VERSION "1.2"

NS_ :

BS_:

BU_: RPI STM32_LEFT STM32_RIGHT ESP32_AUX

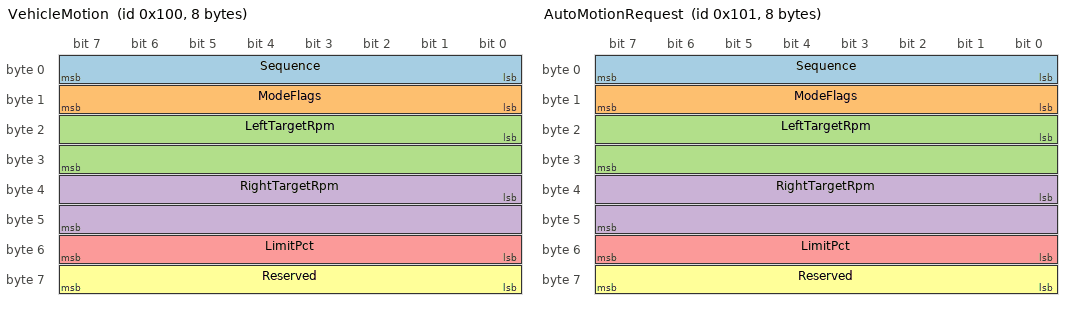
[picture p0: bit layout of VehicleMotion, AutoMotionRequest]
BO_ 256 VehicleMotion: 8 ESP32_AUX
 SG_ Sequence : 0|8@1+ (1,0) [0|255] "" STM32_LEFT,STM32_RIGHT
 SG_ ModeFlags : 8|8@1+ (1,0) [0|255] "" STM32_LEFT,STM32_RIGHT
 SG_ LeftTargetRpm : 16|16@1- (1,0) [-32768|32767] "rpm" STM32_LEFT
 SG_ RightTargetRpm : 32|16@1- (1,0) [-32768|32767] "rpm" STM32_RIGHT
 SG_ LimitPct : 48|8@1+ (1,0) [0|100] "%" STM32_LEFT,STM32_RIGHT
 SG_ Reserved : 56|8@1+ (1,0) [0|255] "" STM32_LEFT,STM32_RIGHT

BO_ 257 AutoMotionRequest: 8 RPI
 SG_ Sequence : 0|8@1+ (1,0) [0|255] "" ESP32_AUX
 SG_ ModeFlags : 8|8@1+ (1,0) [0|255] "" ESP32_AUX
 SG_ LeftTargetRpm : 16|16@1- (1,0) [-32768|32767] "rpm" ESP32_AUX
 SG_ RightTargetRpm : 32|16@1- (1,0) [-32768|32767] "rpm" ESP32_AUX
 SG_ LimitPct : 48|8@1+ (1,0) [0|100] "%" ESP32_AUX
 SG_ Reserved : 56|8@1+ (1,0) [0|255] "" ESP32_AUX

BO_ 272 SystemEnable: 2 ESP32_AUX
 SG_ Enabled : 0|8@1+ (1,0) [0|1] "" STM32_LEFT,STM32_RIGHT,RPI
 SG_ EmergencyStop : 8|8@1+ (1,0) [0|1] "" STM32_LEFT,STM32_RIGHT,RPI

BO_ 273 AutoEnableRequest: 2 RPI
 SG_ Enabled : 0|8@1+ (1,0) [0|1] "" ESP32_AUX
 SG_ EmergencyStop : 8|8@1+ (1,0) [0|1] "" ESP32_AUX

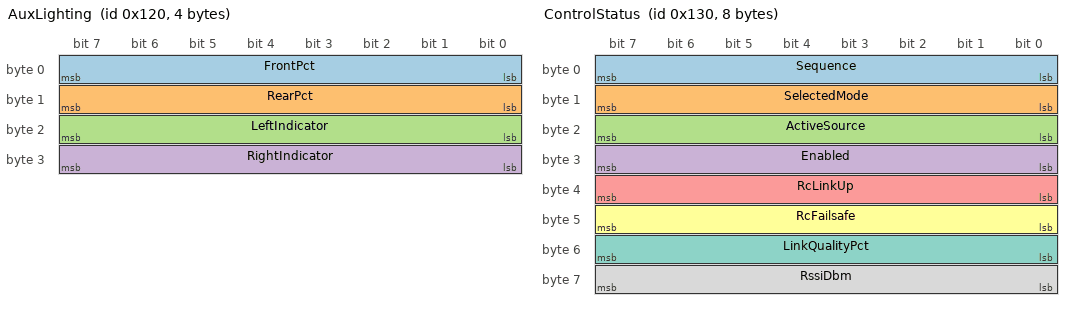
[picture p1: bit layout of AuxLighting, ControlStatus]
BO_ 288 AuxLighting: 4 RPI
 SG_ FrontPct : 0|8@1+ (1,0) [0|100] "%" ESP32_AUX
 SG_ RearPct : 8|8@1+ (1,0) [0|100] "%" ESP32_AUX
 SG_ LeftIndicator : 16|8@1+ (1,0) [0|1] "" ESP32_AUX
 SG_ RightIndicator : 24|8@1+ (1,0) [0|1] "" ESP32_AUX

BO_ 304 ControlStatus: 8 ESP32_AUX
 SG_ Sequence : 0|8@1+ (1,0) [0|255] "" RPI
 SG_ SelectedMode : 8|8@1+ (1,0) [0|2] "" RPI
 SG_ ActiveSource : 16|8@1+ (1,0) [0|2] "" RPI
 SG_ Enabled : 24|8@1+ (1,0) [0|1] "" RPI
 SG_ RcLinkUp : 32|8@1+ (1,0) [0|1] "" RPI
 SG_ RcFailsafe : 40|8@1+ (1,0) [0|1] "" RPI
 SG_ LinkQualityPct : 48|8@1+ (1,0) [0|100] "%" RPI
 SG_ RssiDbm : 56|8@1- (1,0) [-128|127] "dBm" RPI

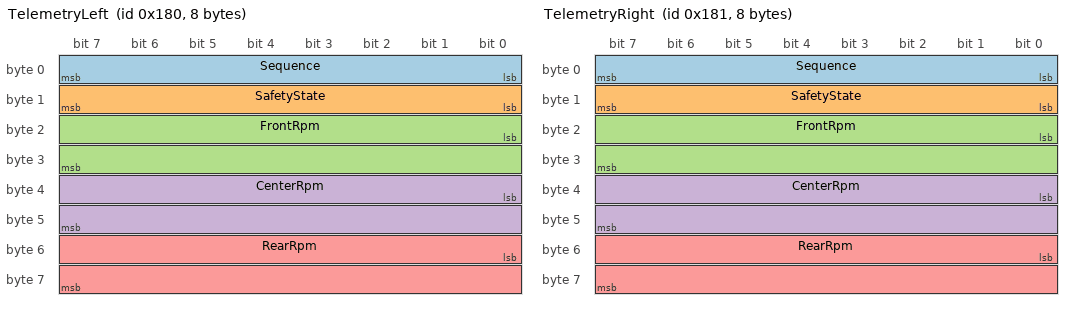
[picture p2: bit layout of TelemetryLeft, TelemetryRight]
BO_ 384 TelemetryLeft: 8 STM32_LEFT
 SG_ Sequence : 0|8@1+ (1,0) [0|255] "" RPI,ESP32_AUX
 SG_ SafetyState : 8|8@1+ (1,0) [0|255] "" RPI,ESP32_AUX
 SG_ FrontRpm : 16|16@1- (1,0) [-32768|32767] "rpm" RPI,ESP32_AUX
 SG_ CenterRpm : 32|16@1- (1,0) [-32768|32767] "rpm" RPI,ESP32_AUX
 SG_ RearRpm : 48|16@1- (1,0) [-32768|32767] "rpm" RPI,ESP32_AUX

BO_ 385 TelemetryRight: 8 STM32_RIGHT
 SG_ Sequence : 0|8@1+ (1,0) [0|255] "" RPI,ESP32_AUX
 SG_ SafetyState : 8|8@1+ (1,0) [0|255] "" RPI,ESP32_AUX
 SG_ FrontRpm : 16|16@1- (1,0) [-32768|32767] "rpm" RPI,ESP32_AUX
 SG_ CenterRpm : 32|16@1- (1,0) [-32768|32767] "rpm" RPI,ESP32_AUX
 SG_ RearRpm : 48|16@1- (1,0) [-32768|32767] "rpm" RPI,ESP32_AUX

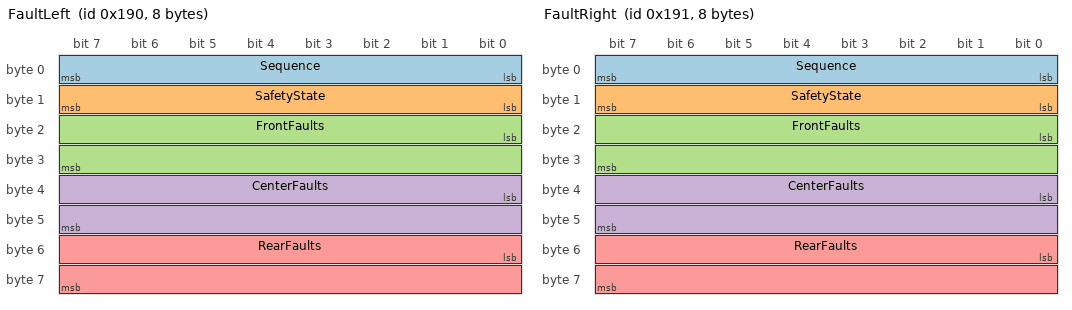
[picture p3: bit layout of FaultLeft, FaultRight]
BO_ 400 FaultLeft: 8 STM32_LEFT
 SG_ Sequence : 0|8@1+ (1,0) [0|255] "" RPI,ESP32_AUX
 SG_ SafetyState : 8|8@1+ (1,0) [0|255] "" RPI,ESP32_AUX
 SG_ FrontFaults : 16|16@1+ (1,0) [0|65535] "" RPI,ESP32_AUX
 SG_ CenterFaults : 32|16@1+ (1,0) [0|65535] "" RPI,ESP32_AUX
 SG_ RearFaults : 48|16@1+ (1,0) [0|65535] "" RPI,ESP32_AUX

BO_ 401 FaultRight: 8 STM32_RIGHT
 SG_ Sequence : 0|8@1+ (1,0) [0|255] "" RPI,ESP32_AUX
 SG_ SafetyState : 8|8@1+ (1,0) [0|255] "" RPI,ESP32_AUX
 SG_ FrontFaults : 16|16@1+ (1,0) [0|65535] "" RPI,ESP32_AUX
 SG_ CenterFaults : 32|16@1+ (1,0) [0|65535] "" RPI,ESP32_AUX
 SG_ RearFaults : 48|16@1+ (1,0) [0|65535] "" RPI,ESP32_AUX

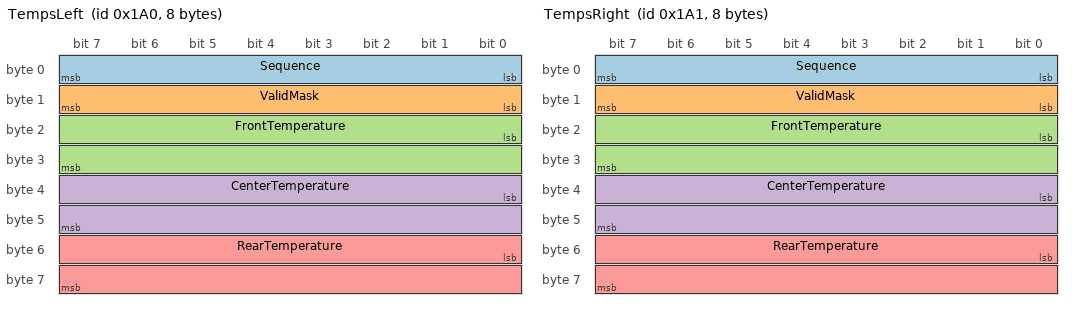
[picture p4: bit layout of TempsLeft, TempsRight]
BO_ 416 TempsLeft: 8 STM32_LEFT
 SG_ Sequence : 0|8@1+ (1,0) [0|255] "" RPI,ESP32_AUX
 SG_ ValidMask : 8|8@1+ (1,0) [0|7] "" RPI,ESP32_AUX
 SG_ FrontTemperature : 16|16@1- (0.01,0) [-327.68|327.67] "degC" RPI,ESP32_AUX
 SG_ CenterTemperature : 32|16@1- (0.01,0) [-327.68|327.67] "degC" RPI,ESP32_AUX
 SG_ RearTemperature : 48|16@1- (0.01,0) [-327.68|327.67] "degC" RPI,ESP32_AUX

BO_ 417 TempsRight: 8 STM32_RIGHT
 SG_ Sequence : 0|8@1+ (1,0) [0|255] "" RPI,ESP32_AUX
 SG_ ValidMask : 8|8@1+ (1,0) [0|7] "" RPI,ESP32_AUX
 SG_ FrontTemperature : 16|16@1- (0.01,0) [-327.68|327.67] "degC" RPI,ESP32_AUX
 SG_ CenterTemperature : 32|16@1- (0.01,0) [-327.68|327.67] "degC" RPI,ESP32_AUX
 SG_ RearTemperature : 48|16@1- (0.01,0) [-327.68|327.67] "degC" RPI,ESP32_AUX

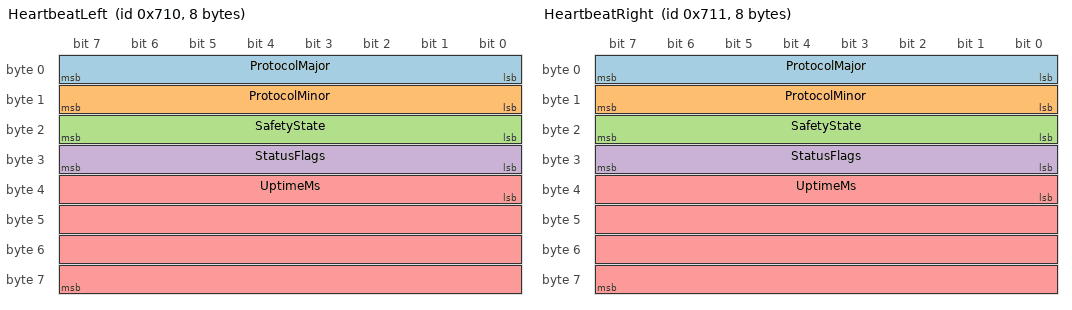
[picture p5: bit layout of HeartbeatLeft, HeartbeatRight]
BO_ 1808 HeartbeatLeft: 8 STM32_LEFT
 SG_ ProtocolMajor : 0|8@1+ (1,0) [0|255] "" RPI,ESP32_AUX
 SG_ ProtocolMinor : 8|8@1+ (1,0) [0|255] "" RPI,ESP32_AUX
 SG_ SafetyState : 16|8@1+ (1,0) [0|255] "" RPI,ESP32_AUX
 SG_ StatusFlags : 24|8@1+ (1,0) [0|255] "" RPI,ESP32_AUX
 SG_ UptimeMs : 32|32@1+ (1,0) [0|4294967295] "ms" RPI,ESP32_AUX

BO_ 1809 HeartbeatRight: 8 STM32_RIGHT
 SG_ ProtocolMajor : 0|8@1+ (1,0) [0|255] "" RPI,ESP32_AUX
 SG_ ProtocolMinor : 8|8@1+ (1,0) [0|255] "" RPI,ESP32_AUX
 SG_ SafetyState : 16|8@1+ (1,0) [0|255] "" RPI,ESP32_AUX
 SG_ StatusFlags : 24|8@1+ (1,0) [0|255] "" RPI,ESP32_AUX
 SG_ UptimeMs : 32|32@1+ (1,0) [0|4294967295] "ms" RPI,ESP32_AUX

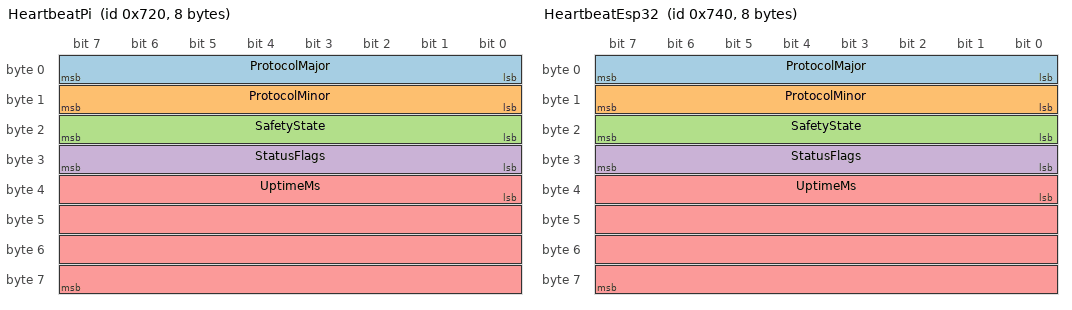
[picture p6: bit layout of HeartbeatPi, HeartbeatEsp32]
BO_ 1824 HeartbeatPi: 8 RPI
 SG_ ProtocolMajor : 0|8@1+ (1,0) [0|255] "" STM32_LEFT,STM32_RIGHT,ESP32_AUX
 SG_ ProtocolMinor : 8|8@1+ (1,0) [0|255] "" STM32_LEFT,STM32_RIGHT,ESP32_AUX
 SG_ SafetyState : 16|8@1+ (1,0) [0|255] "" STM32_LEFT,STM32_RIGHT,ESP32_AUX
 SG_ StatusFlags : 24|8@1+ (1,0) [0|255] "" STM32_LEFT,STM32_RIGHT,ESP32_AUX
 SG_ UptimeMs : 32|32@1+ (1,0) [0|4294967295] "ms" STM32_LEFT,STM32_RIGHT,ESP32_AUX

BO_ 1856 HeartbeatEsp32: 8 ESP32_AUX
 SG_ ProtocolMajor : 0|8@1+ (1,0) [0|255] "" RPI,STM32_LEFT,STM32_RIGHT
 SG_ ProtocolMinor : 8|8@1+ (1,0) [0|255] "" RPI,STM32_LEFT,STM32_RIGHT
 SG_ SafetyState : 16|8@1+ (1,0) [0|255] "" RPI,STM32_LEFT,STM32_RIGHT
 SG_ StatusFlags : 24|8@1+ (1,0) [0|255] "" RPI,STM32_LEFT,STM32_RIGHT
 SG_ UptimeMs : 32|32@1+ (1,0) [0|4294967295] "ms" RPI,STM32_LEFT,STM32_RIGHT

CM_ "Machine-readable mirror of shared/can/ugv_can_protocol.h. Multi-byte signals are little-endian.";
